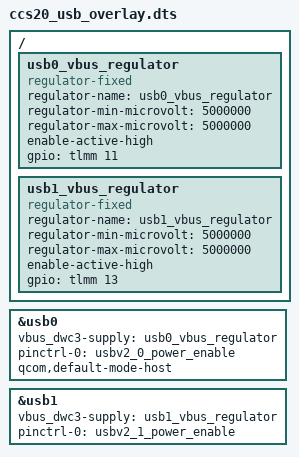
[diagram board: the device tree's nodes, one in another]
/*
 * USB consumers / regulators for CCS20 - generated by usb_dts_tool from the PinMux workbook.
 * Every NEEDS REVIEW comment is an open decision; nothing marked so is verified.
 * Format: default format (the vendor BSP style of the samples: tabs, mux{} / config{}, 'label: label').
 */

/ {
	usb0_vbus_regulator: usb0_vbus_regulator {
		compatible = "regulator-fixed";
		regulator-name = "usb0_vbus_regulator";
		regulator-min-microvolt = <5000000>;
		regulator-max-microvolt = <5000000>;
		enable-active-high;
		gpio = <&tlmm 11 GPIO_ACTIVE_HIGH>;
	};

	usb1_vbus_regulator: usb1_vbus_regulator {
		compatible = "regulator-fixed";
		regulator-name = "usb1_vbus_regulator";
		regulator-min-microvolt = <5000000>;
		regulator-max-microvolt = <5000000>;
		enable-active-high;
		gpio = <&tlmm 13 GPIO_ACTIVE_HIGH>;
	};
};

&usb0 {
	status = "okay";
	vbus_dwc3-supply = <&usb0_vbus_regulator>;
	pinctrl-names = "default";
	pinctrl-0 = <&usbv2_0_power_enable>;
	qcom,default-mode-host;
};

&usb1 {
	status = "okay";
	vbus_dwc3-supply = <&usb1_vbus_regulator>;
	pinctrl-names = "default";
	pinctrl-0 = <&usbv2_1_power_enable>;
	/* NEEDS REVIEW: qcom,default-mode-host is only confirmed for usb0 - add it if this instance should default to host mode. */
};
